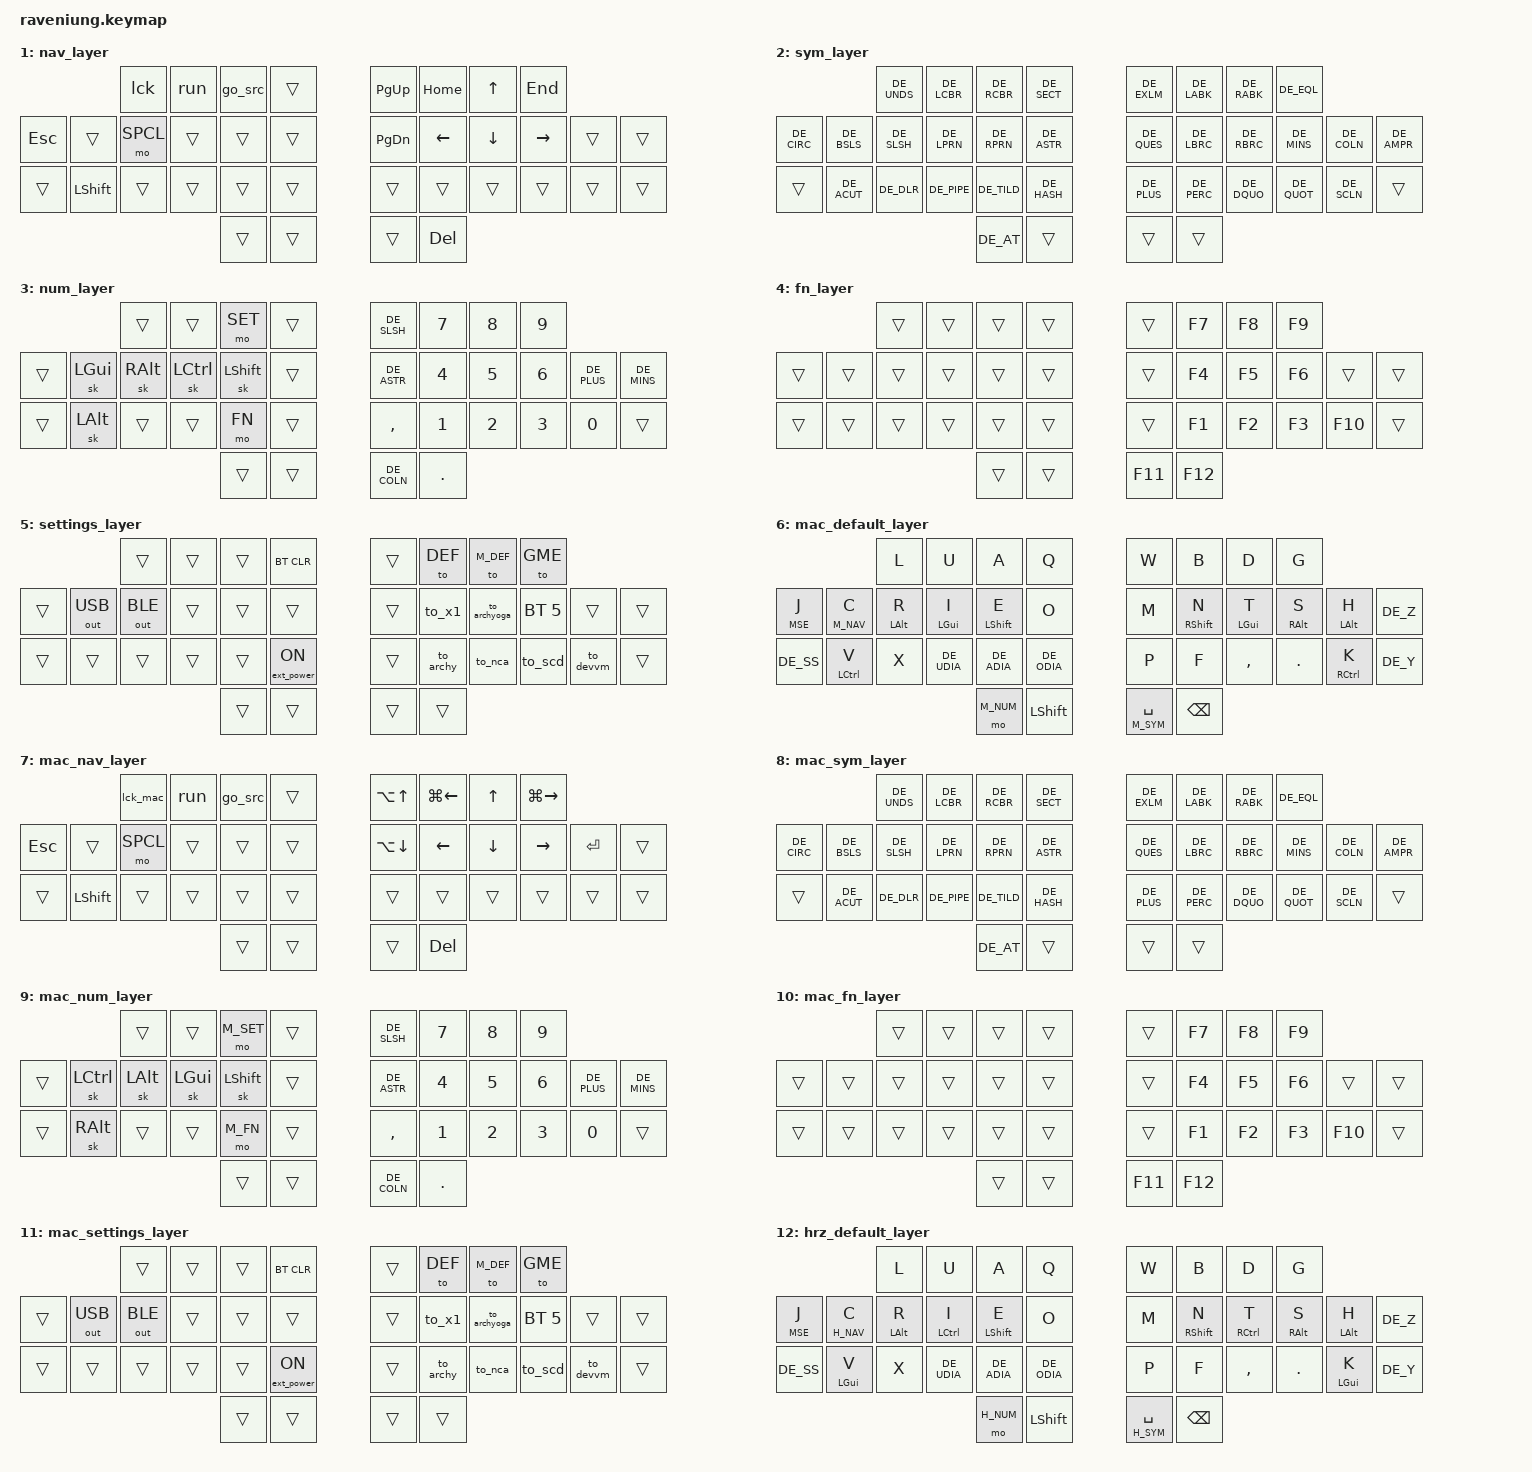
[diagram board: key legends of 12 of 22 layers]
/*
 * Copyright (c) 2020 The ZMK Contributors
 *
 * SPDX-License-Identifier: MIT
 */

#include <behaviors.dtsi>
#include <dt-bindings/zmk/keys.h>
#include <dt-bindings/zmk/bt.h>
#include <dt-bindings/zmk/pointing.h>
#include <dt-bindings/zmk/outputs.h>
#include <dt-bindings/zmk/ext_power.h>
#include <dt-bindings/zmk/input_transform.h>
#include <input/processors.dtsi>
#include "keymap_german.h"

// Layers
// Win and Linux
#define DEF     0
#define NAV     1
#define SYM     2
#define NUM     3
#define FN      4
#define SET     5

// Mac
#define M_DEF   6
#define M_NAV   7
#define M_SYM   8
#define M_NUM   9
#define M_FN    10
#define M_SET   11

// Stupid workaround for Horizon Client on MacOS
#define H_DEF   12
#define H_NAV   13
#define H_SYM   14
#define H_NUM   15
#define H_FN    16
#define H_SET   17

// Game
#define GME     18

// Global
#define MSE     19
#define SPCL    20
#define SCRL    21

// Special shortcuts
#define ________     &trans
#define TODO         &trans
#define DEL_W        &kp LC(BSPC)
#define SPACE_SYM    &lt SYM SPACE
#define SPACE_M_SYM  &lt M_SYM SPACE
#define SPACE_H_SYM  &lt H_SYM SPACE
#define J_MSE        &lt MSE J
#define C_NAV        &lt NAV C
#define C_M_NAV      &lt M_NAV C
#define C_H_NAV      &lt H_NAV C
#define EXT_ON       &ext_power EP_ON
#define SCRL_D       &msc SCRL_DOWN
#define SCRL_U       &msc SCRL_UP

#define BT_1       &bt BT_SEL 0
#define BT_2       &bt BT_SEL 1
#define BT_3       &bt BT_SEL 2
#define BT_4       &bt BT_SEL 3
#define BT_5       &bt BT_SEL 4
#define BT_6       &bt BT_SEL 5
#define BT_CLEAR   &bt BT_CLR

// home row mod left
#define ALT_R &hm LALT R
#define CTL_I &hm LCTRL I
#define SFT_E &hm LSHIFT E
#define GUI_V &hm LGUI V

// home row mod right
#define SFT_N    &hm RSHIFT N
#define CTL_T    &hm RCTRL T
#define RALT_S   &hm RALT S
#define LALT_H    &hm LALT H
#define LGUI_K    &hm LGUI K

// home row mod mac
#define CMD_I  &hm LGUI I
#define CMD_T  &hm LGUI T
#define CTL_H  &hm RCTRL H
#define CTL_K  &hm RCTRL K
#define CTL_V  &hm LCTRL V

// mac shortcuts
#define M_HME    &kp LG(LEFT)
#define M_END    &kp LG(RIGHT)
#define M_PUP    &kp LA(UP)
#define M_PDWN   &kp LA(DOWN)
#define M_MC     &kp C_AC_DESKTOP_SHOW_ALL_WINDOWS

&sk {
        release-after-ms = <3000>;
};

/ {
    glidepoint_listener {
        compatible = "zmk,input-listener";
        device = <&glidepoint>;
        input-processors 
//          = <&zip_temp_layer MSE 1200>
          = <&zip_xy_scaler 2 1>;

        scroll {
            layers = <SCRL>;
            input-processors
              = <&zip_xy_scaler 1 32>
              , <&zip_xy_transform INPUT_TRANSFORM_Y_INVERT> /* natural scroll */
              , <&zip_xy_to_scroll_mapper>
            ;
        };
    };

    macros {

        ZMK_MACRO(go_src,
            wait-ms = <30>;
            tap-ms = <40>;
            bindings
                = <&macro_press   &kp LALT>
                , <&macro_tap     &kp F1>
                , <&macro_release &kp LALT>
                , <&macro_wait_time 2000>
                , <&macro_tap     &kp RET>
                ;
        )

        ZMK_MACRO(run,
            wait-ms = <30>;
            tap-ms = <40>;
            bindings
                = <&macro_press   &kp LALT>
                , <&macro_press   &kp LSHFT>
                , <&macro_tap     &kp F10>
                , <&macro_release &kp LSHFT>
                , <&macro_release &kp LALT>
                ;
        )

        ZMK_MACRO(lck,
            wait-ms = <30>;
            tap-ms = <40>;
            bindings
                = <&macro_press   &kp LGUI>
                , <&macro_tap     &kp L>
                , <&macro_release &kp LGUI>
                ;
        )

        ZMK_MACRO(lck_mac,
            wait-ms = <30>;
            tap-ms = <40>;
            bindings
                = <&macro_press   &kp LGUI>
                , <&macro_press   &kp LCTL>
                , <&macro_tap     &kp Q>
                , <&macro_release &kp LCTL>
                , <&macro_release &kp LGUI>
                ;
        )
        
        ZMK_MACRO(to_archy,
            wait-ms = <30>;
            tap-ms = <40>;
            bindings
                = <&macro_tap  BT_1>
                , <&macro_tap  &to DEF>
                ;
        )

        ZMK_MACRO(to_archyoga,
            wait-ms = <30>;
            tap-ms = <40>;
            bindings
                = <&macro_tap  BT_5>
                , <&macro_tap  &to DEF>
                ;
        )

        ZMK_MACRO(to_scd,
            wait-ms = <30>;
            tap-ms = <40>;
            bindings
                = <&macro_tap  BT_2>
                , <&macro_tap  &to M_DEF>
                , <&macro_press   &kp LALT>
                , <&macro_press   &kp LGUI>
                , <&macro_press   &kp LSHFT>
                , <&macro_tap     &kp RIGHT>
                , <&macro_release &kp LSHFT>
                , <&macro_release &kp LGUI>
                , <&macro_release &kp LALT>
                , <&macro_tap  &to H_DEF>
                , <&macro_press   &kp LWIN>
                , <&macro_press   &kp LCTL>
                , <&macro_tap     &kp LEFT>
                , <&macro_release &kp LCTL>
                , <&macro_release &kp LWIN>
                ;
        )

        ZMK_MACRO(to_nca,
            wait-ms = <30>;
            tap-ms = <40>;
            bindings
                = <&macro_tap  BT_2>
                , <&macro_tap  &to M_DEF>
                , <&macro_press   &kp LALT>
                , <&macro_press   &kp LGUI>
                , <&macro_press   &kp LSHFT>
                , <&macro_tap     &kp LEFT>
                , <&macro_release &kp LSHFT>
                , <&macro_release &kp LGUI>
                , <&macro_release &kp LALT>
                ;
        )

        ZMK_MACRO(to_devvm,
            wait-ms = <30>;
            tap-ms = <40>;
            bindings
                = <&macro_tap  BT_2>
                , <&macro_tap    &to H_DEF>
                , <&macro_press   &kp LWIN>
                , <&macro_press   &kp LCTL>
                , <&macro_tap     &kp RIGHT>
                , <&macro_release &kp LCTL>
                , <&macro_release &kp LWIN>
                ;
        )

        ZMK_MACRO(to_x1,
            wait-ms = <30>;
            tap-ms = <40>;
            bindings
                = <&macro_tap  BT_4>
                , <&macro_tap  &to DEF>
                ;
        )

        ZMK_MACRO(m_spec,
            wait-ms = <30>;
            tap-ms = <30>;
            bindings
                = <&macro_tap &kp DE_AT &kp M &kp E &kp DOT &kp C &kp O &kp M>                ;
        )

        ZMK_MACRO(mas_spec,
            wait-ms = <30>;
            tap-ms = <30>;
            bindings
                = <&macro_tap &kp DE_AT &kp I &kp C &kp L &kp O &kp U &kp D &kp DOT &kp C &kp O &kp M>                ;
        )

        ZMK_MACRO(maz_spec,
            wait-ms = <30>;
            tap-ms = <30>;
            bindings
                = <&macro_tap &kp DE_AT &kp G &kp M &kp A &kp I &kp L &kp DOT &kp C &kp O &kp M>
                ;
        )

    };


    combos {
        compatible = "zmk,combos";

        combo_tab {
            timeout-ms = <50>;
            key-positions = <9 21>;
            bindings = <&kp TAB>;
        };

        combo_enter {
            timeout-ms = <50>;
            key-positions = <18 30>;
            bindings = <&kp RET>;
        };
        
        combo_esc {
            timeout-ms = <50>;
            key-positions = <8 20>;
            bindings = <&kp ESC>;
        };

    };

    behaviors {
        hm: homerow_mods {
                    compatible = "zmk,behavior-hold-tap";
                    #binding-cells = <2>;
                    tapping-term-ms = <180>;
                    quick-tap-ms = <0>;
                    flavor = "tap-preferred";
                    bindings = <&kp>, <&kp>;
            };
    };


    keymap {
        compatible = "zmk,keymap";

        default_layer {
            bindings = <
                             &kp B   &kp Y    &kp O     &kp U            &kp L      &kp D      &kp W    &kp V   
                &kp LSHIFT   &kp C   &kp I    &kp E     &kp A            &kp H      &kp T      &kp S    &kp N   &kp BSPC
                &mt LCTRL Q  &kp G   &kp X    &kp J     &kp K            &kp R      &kp M     &kp F    &kp P   &kp Z
                             &kp TAB  &kp RET &kp TAB     &kp SPACE &kp RET  &kp BSPC
            >;
        };

        nav_layer {
            bindings = <
            	                    &lck      &run      &go_src   ________             &kp PG_UP  &kp HOME  &kp UP    &kp END
            	&kp ESC  ________   &mo SPCL  ________  ________  ________             &kp PG_DN  &kp LEFT  &kp DOWN  &kp RIGHT  ________  ________
            	TODO     &kp LSHFT  ________  ________  ________  ________             ________   ________  ________  ________   ________  ________
            	                                        ________  ________             ________   &kp DEL
            >;
        };

        sym_layer {
        // ---------------------------------------------------------------------
        // |  ^  |  _  |  {  |  }  |  §  |       |  !  |  <  |  >  |  =  |  &  |
        // |  \  |  /  |  (  |  )  |  *  |       |  ?  |  [  |  ]  |  -  |  :  |
        // |  `  |  $  |  |  |  ~  |  #  |       |  +  |  %  |  "  |  '  |  ;  |
        //                   | --- | --- |       | --- | --- |
          	bindings = <
                                         &kp DE_UNDS  &kp DE_LCBR  &kp DE_RCBR  &kp DE_SECT          &kp DE_EXLM  &kp DE_LABK  &kp DE_RABK  &kp DE_EQL
               &kp DE_CIRC  &kp DE_BSLS  &kp DE_SLSH  &kp DE_LPRN  &kp DE_RPRN  &kp DE_ASTR          &kp DE_QUES  &kp DE_LBRC  &kp DE_RBRC  &kp DE_MINS  &kp DE_COLN  &kp DE_AMPR
               TODO         &kp DE_ACUT  &kp DE_DLR   &kp DE_PIPE  &kp DE_TILD  &kp DE_HASH          &kp DE_PLUS  &kp DE_PERC  &kp DE_DQUO  &kp DE_QUOT  &kp DE_SCLN  TODO
        	                                                         &kp DE_AT    ________             ________     ________
          	>;
        };

        num_layer {
            bindings = <
                                    ________  ________  &mo SET     ________         &kp DE_SLSH  &kp N7   &kp N8    &kp N9
                ________  &sk LGUI  &sk RALT  &sk LCTRL &sk LSHIFT  ________         &kp DE_ASTR  &kp N4   &kp N5    &kp N6  &kp DE_PLUS  &kp DE_MINS
                TODO      &sk LALT  ________  ________  &mo FN      ________         &kp COMMA    &kp N1   &kp N2    &kp N3  &kp N0       TODO
                                                        ________    ________         &kp DE_COLN  &kp DOT
            >;
        };

        fn_layer {
            bindings = <
                                    ________  ________  ________  ________          ________  &kp F7  &kp F8  &kp F9
                ________  ________  ________  ________  ________  ________          ________  &kp F4  &kp F5  &kp F6  ________  ________
                TODO      ________  ________  ________  ________  ________          ________  &kp F1  &kp F2  &kp F3  &kp F10   TODO
                                                        ________  ________          &kp F11   &kp F12
            >;
        };

        settings_layer {
            bindings = <
                                    ________      ________  ________  BT_CLEAR          ________  &to DEF    &to M_DEF     &to GME
                TODO  &out OUT_USB  &out OUT_BLE  ________  ________  ________          ________  &to_x1     &to_archyoga  BT_6     ________   ________
                TODO  ________      ________      ________  ________  EXT_ON            ________  &to_archy  &to_nca       &to_scd  &to_devvm  TODO
                                                            ________  ________          ________  ________
            >;
        };






        mac_default_layer {
            bindings = <
                                    &kp L  &kp U        &kp A        &kp Q                    &kp W        &kp B     &kp D      &kp G
                J_MSE      C_M_NAV  ALT_R  CMD_I        SFT_E        &kp O                    &kp M        SFT_N     CMD_T      RALT_S   LALT_H  &kp DE_Z
                &kp DE_SS  CTL_V    &kp X  &kp DE_UDIA  &kp DE_ADIA  &kp DE_ODIA              &kp P        &kp F     &kp COMMA  &kp DOT  CTL_K   &kp DE_Y
                                                        &mo M_NUM    &kp LSHFT                SPACE_M_SYM    &kp BSPC
             >;
        };

        mac_nav_layer {
            bindings = <
            	                   &lck_mac  &run       &go_src    ________             M_PUP     M_HME      &kp UP    M_END
            	&kp ESC  ________  &mo SPCL  ________   ________   ________             M_PDWN    &kp LEFT   &kp DOWN  &kp RIGHT  &kp RET   ________
            	TODO     &kp LSHFT ________  ________   ________   ________             ________  ________   ________  ________   ________  ________
            	                                        ________   ________             ________  &kp DEL
      			>;
        };

        mac_sym_layer {
        // ---------------------------------------------------------------------
        // |  ^  |  _  |  {  |  }  |  §  |       |  !  |  <  |  >  |  =  |  &  |
        // |  \  |  /  |  (  |  )  |  *  |       |  ?  |  [  |  ]  |  -  |  :  |
        // |  `  |  $  |  |  |  ~  |  #  |       |  +  |  %  |  "  |  '  |  ;  |
        //                   | --- | --- |       | --- | --- |
          	bindings = <
                                         &kp DE_UNDS  &kp DE_LCBR  &kp DE_RCBR  &kp DE_SECT          &kp DE_EXLM  &kp DE_LABK  &kp DE_RABK  &kp DE_EQL
               &kp DE_CIRC  &kp DE_BSLS  &kp DE_SLSH  &kp DE_LPRN  &kp DE_RPRN  &kp DE_ASTR          &kp DE_QUES  &kp DE_LBRC  &kp DE_RBRC  &kp DE_MINS  &kp DE_COLN  &kp DE_AMPR
               TODO         &kp DE_ACUT  &kp DE_DLR   &kp DE_PIPE  &kp DE_TILD  &kp DE_HASH          &kp DE_PLUS  &kp DE_PERC  &kp DE_DQUO  &kp DE_QUOT  &kp DE_SCLN  TODO
        	                                                         &kp DE_AT    ________             ________     ________
          	>;
        };

        mac_num_layer {
            bindings = <
                                     ________  ________  &mo M_SET   ________          &kp DE_SLSH  &kp N7   &kp N8  &kp N9
                ________  &sk LCTRL  &sk LALT  &sk LGUI  &sk LSHIFT  ________          &kp DE_ASTR  &kp N4   &kp N5  &kp N6  &kp DE_PLUS  &kp DE_MINS
                TODO      &sk RALT   ________  ________  &mo M_FN    ________          &kp COMMA    &kp N1   &kp N2  &kp N3  &kp N0       TODO
                                                         ________    ________          &kp DE_COLN  &kp DOT
            >;
        };

        mac_fn_layer {
            bindings = <
                                    ________  ________  ________  ________          ________  &kp F7  &kp F8  &kp F9
                ________  ________  ________  ________  ________  ________          ________  &kp F4  &kp F5  &kp F6  ________  ________
                TODO      ________  ________  ________  ________  ________          ________  &kp F1  &kp F2  &kp F3  &kp F10   TODO
                                                        ________  ________          &kp F11   &kp F12
            >;
        };

        mac_settings_layer {
            bindings = <
                                    ________      ________  ________  BT_CLEAR          ________  &to DEF    &to M_DEF     &to GME
                TODO  &out OUT_USB  &out OUT_BLE  ________  ________  ________          ________  &to_x1     &to_archyoga  BT_6     ________   ________
                TODO  ________      ________      ________  ________  EXT_ON            ________  &to_archy  &to_nca       &to_scd  &to_devvm  TODO
                                                            ________  ________          ________  ________
            >;
        };









        hrz_default_layer {
            bindings = <
                                    &kp L  &kp U        &kp A        &kp Q                   &kp W        &kp B      &kp D      &kp G
                J_MSE      C_H_NAV  ALT_R  CTL_I        SFT_E        &kp O                   &kp M        SFT_N      CTL_T      RALT_S   LALT_H  &kp DE_Z
                &kp DE_SS  GUI_V    &kp X  &kp DE_UDIA  &kp DE_ADIA  &kp DE_ODIA             &kp P        &kp F      &kp COMMA  &kp DOT  LGUI_K  &kp DE_Y
                                                        &mo H_NUM    &kp LSHFT               SPACE_H_SYM  &kp BSPC
             >;
        };

        hrz_nav_layer {
            bindings = <
            	                    &lck      &run      &go_src   ________             &kp PG_UP  &kp HOME  &kp UP    &kp END
            	&kp ESC  ________   &mo SPCL  ________  ________  ________             &kp PG_DN  &kp LEFT  &kp DOWN  &kp RIGHT  ________  ________
            	TODO     &kp LSHFT  ________  ________  ________  ________             ________   ________  ________  ________   ________  ________
            	                                        ________  ________             ________   &kp DEL
            >;
        };

        hrz_sym_layer {
        // ---------------------------------------------------------------------
        // |  ^  |  _  |  {  |  }  |  §  |       |  !  |  <  |  >  |  =  |  &  |
        // |  \  |  /  |  (  |  )  |  *  |       |  ?  |  [  |  ]  |  -  |  :  |
        // |  `  |  $  |  |  |  ~  |  #  |       |  +  |  %  |  "  |  '  |  ;  |
        //                   | --- | --- |       | --- | --- |
        	  bindings = <
                                         &kp DE_UNDS  &kp LA(N8)   &kp LA(N9)   &kp DE_SECT          &kp DE_EXLM  &kp DE_LABK  &kp DE_RABK  &kp DE_EQL
               &kp DE_CIRC  &kp DE_BSLS  &kp DE_SLSH  &kp DE_LPRN  &kp DE_RPRN  &kp DE_ASTR          &kp DE_QUES  &kp RA(N5)   &kp RA(N6)   &kp DE_MINS  &kp DE_COLN  &kp DE_AMPR
               ________     &kp EQUAL    &kp DE_DLR   &kp DE_PIPE  &kp DE_TILD  &kp DE_HASH          &kp DE_PLUS  &kp DE_PERC  &kp DE_DQUO  &kp DE_QUOT  &kp DE_SCLN  ________
        	                                                         &kp DE_AT    ________             ________     ________
        	  >;
        };

        hrz_num_layer {
            bindings = <
                                    ________  ________  &mo H_SET   ________         &kp DE_SLSH  &kp N7   &kp N8    &kp N9
                ________  &sk LGUI  &sk RALT  &sk LCTRL &sk LSHIFT  ________         &kp DE_ASTR  &kp N4   &kp N5    &kp N6  &kp DE_PLUS  &kp DE_MINS
                TODO      &sk LALT  ________  ________  &mo H_FN    ________         &kp COMMA    &kp N1   &kp N2    &kp N3  &kp N0       TODO
                                                        ________    ________         &kp DE_COLN  &kp DOT
            >;
        };

        hrz_fn_layer {
            bindings = <
                                    ________  ________  ________  ________          ________  &kp F7  &kp F8  &kp F9
                ________  ________  ________  ________  ________  ________          ________  &kp F4  &kp F5  &kp F6  ________  ________
                TODO      ________  ________  ________  ________  ________          ________  &kp F1  &kp F2  &kp F3  &kp F10   TODO
                                                        ________  ________          &kp F11   &kp F12
            >;
        };

        hrz_settings_layer {
            bindings = <
                                    ________      ________  ________  BT_CLEAR          ________  &to DEF    &to M_DEF     &to GME
                TODO  &out OUT_USB  &out OUT_BLE  ________  ________  ________          ________  &to_x1     &to_archyoga  BT_6     ________   ________
                TODO  ________      ________      ________  ________  EXT_ON            ________  &to_archy  &to_nca       &to_scd  &to_devvm  TODO
                                                            ________  ________          ________  ________
            >;
        };





 




        game_layer {
            bindings = <
                                 &kp L  &kp U        &kp A        &kp Q                 &kp W      &kp B     &kp D      &kp G
               &kp J      &kp C  &kp R  &kp I        &kp E        &kp O                 &kp M      &kp N     &kp T      &kp S    &kp H  &kp DE_Z
               &kp DE_SS  &kp V  &kp X  &kp DE_UDIA  &kp DE_ADIA  &kp DE_ODIA           &kp P      &kp F     &kp COMMA  &kp DOT  &kp K  &kp DE_Y
                                                     &mo NUM      &kp LSHFT             SPACE_SYM  &kp BSPC
             >;
        };










        mouse_layer {
            bindings = <
                                   &mkp MB4   &mo SCRL   &mkp MB5   ________          ________  ________  ________  ________
                ________ ________  &mkp RCLK  &mkp MCLK  &mkp LCLK  ________          ________  ________  ________  ________  ________  ________
                ________ ________  ________   ________   ________   ________          ________  ________  ________  ________  ________  ________
                                                         &kp LCTRL  &kp LSHFT         ________  ________
            >;
        };

        special_layer {
            bindings = <
                                   ________  ________  ________  &maz_spec         ________  ________  ________  ________
                ________ ________  ________  ________  ________  &mas_spec         ________  ________  ________  ________  ________  ________
                ________ ________  ________  ________  &m_spec   ________          ________  ________  ________  ________  ________  ________
                                                       ________  ________          ________  ________
            >;
        };

        // dummy layer for scrolling with trackpad
        scroll_layer {
            bindings = <
                                   ________  ________  ________  ________          ________  &kp C_PREV      &kp C_PP      &kp C_NEXT
                ________ ________  ________  ________  ________  ________          ________  &kp C_MUTE      &kp C_VOL_DN  &kp C_VOL_UP  ________  ________
                ________ ________  ________  ________  ________  ________          ________  &kp C_BRI_AUTO  &kp C_BRI_DN  &kp C_BRI_UP  ________  ________
                                                       ________  ________          ________  ________
            >;
        };

     };
};
